AUTOSAR XML (schema 314)
package /ComponentType
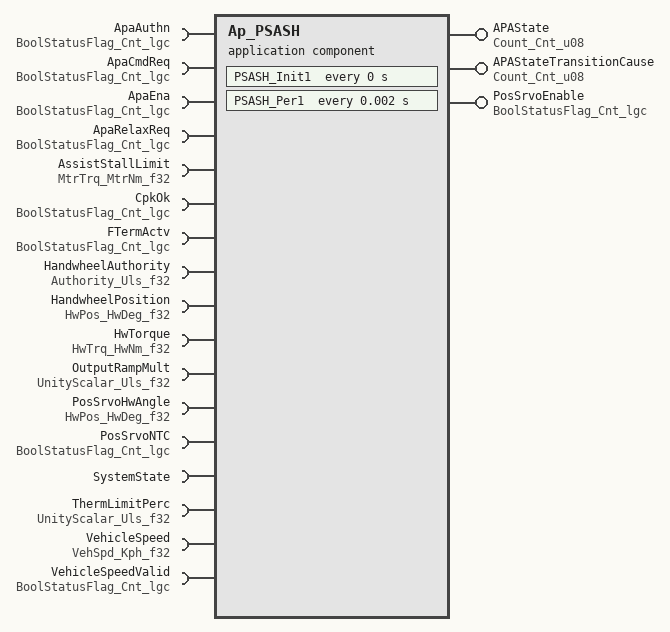
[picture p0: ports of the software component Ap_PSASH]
  application software component type Ap_PSASH
    provide port APAState: unqueued-sender-com-spec{data-element=Cnt_u08, can-invalidate=false, init-value=D_ZERO_CNT_U8}, provided-interface=Count_Cnt_u08
    provide port APAStateTransitionCause: unqueued-sender-com-spec{data-element=Cnt_u08, can-invalidate=false, init-value=D_ZERO_CNT_U8}, provided-interface=Count_Cnt_u08
    provide port PosSrvoEnable: unqueued-sender-com-spec{data-element=Cnt_lgc, can-invalidate=false, init-value=D_FALSE_CNT_LGC}, provided-interface=BoolStatusFlag_Cnt_lgc
    17 x require port:
      ApaAuthn: unqueued-receiver-com-spec{data-element=Cnt_lgc, init-value=D_FALSE_CNT_LGC}, required-interface=BoolStatusFlag_Cnt_lgc
      ApaCmdReq: unqueued-receiver-com-spec{data-element=Cnt_lgc, init-value=D_FALSE_CNT_LGC}, required-interface=BoolStatusFlag_Cnt_lgc
      ApaEna: unqueued-receiver-com-spec{data-element=Cnt_lgc, init-value=D_FALSE_CNT_LGC}, required-interface=BoolStatusFlag_Cnt_lgc
      ApaRelaxReq: unqueued-receiver-com-spec{data-element=Cnt_lgc, init-value=D_FALSE_CNT_LGC}, required-interface=BoolStatusFlag_Cnt_lgc
      AssistStallLimit: unqueued-receiver-com-spec{data-element=MtrNm_f32, init-value=D_MTRTRQCMDHILMT_MTRNM_F32}, required-interface=MtrTrq_MtrNm_f32
      CpkOk: unqueued-receiver-com-spec{data-element=Cnt_lgc, init-value=D_FALSE_CNT_LGC}, required-interface=BoolStatusFlag_Cnt_lgc
      FTermActv: unqueued-receiver-com-spec{data-element=Cnt_lgc, init-value=D_FALSE_CNT_LGC}, required-interface=BoolStatusFlag_Cnt_lgc
      HandwheelAuthority: unqueued-receiver-com-spec{data-element=Uls_f32, init-value=D_ZERO_ULS_F32}, required-interface=Authority_Uls_f32
      HandwheelPosition: unqueued-receiver-com-spec{data-element=HwDeg_f32, init-value=D_ZERO_ULS_F32}, required-interface=HwPos_HwDeg_f32
      HwTorque: unqueued-receiver-com-spec{data-element=HwNm_f32, init-value=D_ZERO_ULS_F32}, required-interface=HwTrq_HwNm_f32
      OutputRampMult: unqueued-receiver-com-spec{data-element=Uls_f32, init-value=D_ZERO_ULS_F32}, required-interface=UnityScalar_Uls_f32
      PosSrvoHwAngle: unqueued-receiver-com-spec{data-element=HwDeg_f32, init-value=D_ZERO_ULS_F32}, required-interface=HwPos_HwDeg_f32
      PosSrvoNTC: unqueued-receiver-com-spec{data-element=Cnt_lgc, init-value=D_FALSE_CNT_LGC}, required-interface=BoolStatusFlag_Cnt_lgc
      SystemState: required-interface=SystemState
      ThermLimitPerc: unqueued-receiver-com-spec{data-element=Uls_f32, init-value=D_ZERO_ULS_F32}, required-interface=UnityScalar_Uls_f32
      VehicleSpeed: unqueued-receiver-com-spec{data-element=Kph_f32, init-value=D_ZERO_ULS_F32}, required-interface=VehSpd_Kph_f32
      VehicleSpeedValid: unqueued-receiver-com-spec{data-element=Cnt_lgc, init-value=D_FALSE_CNT_LGC}, required-interface=BoolStatusFlag_Cnt_lgc
  internal behavior Ap_PSASH_InternalBehavior: component=Ap_PSASH
    timing event PSASH_Init1_InitEvent: start-on-event=PSASH_Init1, period=0
    timing event TMT_PSASH_Per1: start-on-event=PSASH_Per1, period=0.002
    port-api-options:
      enable-take-address=false, indirect-api=false, port=ApaAuthn
      enable-take-address=false, indirect-api=false, port=ApaCmdReq
      enable-take-address=false, indirect-api=false, port=ApaEna
      enable-take-address=false, indirect-api=false, port=ApaRelaxReq
      enable-take-address=false, indirect-api=false, port=APAState
      enable-take-address=false, indirect-api=false, port=APAStateTransitionCause
      enable-take-address=false, indirect-api=false, port=AssistStallLimit
      enable-take-address=false, indirect-api=false, port=CpkOk
      enable-take-address=false, indirect-api=false, port=FTermActv
      enable-take-address=false, indirect-api=false, port=HandwheelAuthority
      enable-take-address=false, indirect-api=false, port=HandwheelPosition
      enable-take-address=false, indirect-api=false, port=HwTorque
      enable-take-address=false, indirect-api=false, port=OutputRampMult
      enable-take-address=false, indirect-api=false, port=PosSrvoEnable
      enable-take-address=false, indirect-api=false, port=PosSrvoHwAngle
      enable-take-address=false, indirect-api=false, port=PosSrvoNTC
      enable-take-address=false, indirect-api=false, port=SystemState
      enable-take-address=false, indirect-api=false, port=ThermLimitPerc
      enable-take-address=false, indirect-api=false, port=VehicleSpeed
      enable-take-address=false, indirect-api=false, port=VehicleSpeedValid
    runnable PSASH_Init1
    runnable PSASH_Per1
      16 x data read access:
        READ_ApaAuthn_Cnt_lgc: data-element=ApaAuthn.Cnt_lgc
        READ_ApaCmdReq_Cnt_lgc: data-element=ApaCmdReq.Cnt_lgc
        READ_ApaEna_Cnt_lgc: data-element=ApaEna.Cnt_lgc
        READ_ApaRelaxReq_Cnt_lgc: data-element=ApaRelaxReq.Cnt_lgc
        READ_AssistStallLimit_MtrNm_f32: data-element=AssistStallLimit.MtrNm_f32
        READ_CpkOk_Cnt_lgc: data-element=CpkOk.Cnt_lgc
        READ_FTermActv_Cnt_lgc: data-element=FTermActv.Cnt_lgc
        READ_HandwheelAuthority_Uls_f32: data-element=HandwheelAuthority.Uls_f32
        READ_HandwheelPosition_HwDeg_f32: data-element=HandwheelPosition.HwDeg_f32
        READ_HwTorque_HwNm_f32: data-element=HwTorque.HwNm_f32
        READ_OutputRampMult_Uls_f32: data-element=OutputRampMult.Uls_f32
        READ_PosSrvoHwAngle_HwDeg_f32: data-element=PosSrvoHwAngle.HwDeg_f32
        READ_PosSrvoNTC_Cnt_lgc: data-element=PosSrvoNTC.Cnt_lgc
        READ_ThermLimitPerc_Uls_f32: data-element=ThermLimitPerc.Uls_f32
        READ_VehicleSpeed_Kph_f32: data-element=VehicleSpeed.Kph_f32
        READ_VehicleSpeedValid_Cnt_lgc: data-element=VehicleSpeedValid.Cnt_lgc
      data write access WRITE_APAState_Cnt_u08: data-element=APAState.Cnt_u08
      data write access WRITE_APAStateTransitionCause_Cnt_u08: data-element=APAStateTransitionCause.Cnt_u08
      data write access WRITE_PosSrvoEnable_Cnt_lgc: data-element=PosSrvoEnable.Cnt_lgc
  swc implementation Ap_PSASH_Implementation: behavior=Ap_PSASH_InternalBehavior
    code-descriptors:
      code Code: type=SRC
